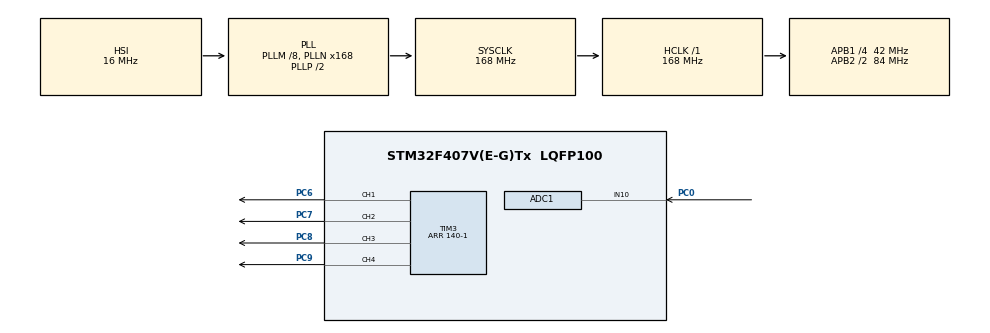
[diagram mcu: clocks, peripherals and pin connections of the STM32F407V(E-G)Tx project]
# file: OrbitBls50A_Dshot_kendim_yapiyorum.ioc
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ADC1.Channel-1\#ChannelRegularConversion=ADC_CHANNEL_10
ADC1.ContinuousConvMode=ENABLE
ADC1.NbrOfConversionFlag=1
ADC1.Rank-1\#ChannelRegularConversion=1
ADC1.SamplingTime-1\#ChannelRegularConversion=ADC_SAMPLETIME_84CYCLES
ADC1.master=1
Dma.Request0=TIM3_CH1/TRIG
Dma.Request1=TIM3_CH2
Dma.Request2=TIM3_CH3
Dma.Request3=TIM3_CH4/UP
Dma.TIM3_CH1/TRIG.0.Direction=DMA_MEMORY_TO_PERIPH
Dma.TIM3_CH1/TRIG.0.FIFOMode=DMA_FIFOMODE_DISABLE
Dma.TIM3_CH1/TRIG.0.Instance=DMA1_Stream4
Dma.TIM3_CH1/TRIG.0.MemDataAlignment=DMA_MDATAALIGN_HALFWORD
Dma.TIM3_CH1/TRIG.0.MemInc=DMA_MINC_ENABLE
Dma.TIM3_CH1/TRIG.0.Mode=DMA_NORMAL
Dma.TIM3_CH1/TRIG.0.PeriphDataAlignment=DMA_PDATAALIGN_HALFWORD
Dma.TIM3_CH1/TRIG.0.PeriphInc=DMA_PINC_DISABLE
Dma.TIM3_CH1/TRIG.0.Priority=DMA_PRIORITY_HIGH
Dma.TIM3_CH2.1.Direction=DMA_MEMORY_TO_PERIPH
Dma.TIM3_CH2.1.FIFOMode=DMA_FIFOMODE_DISABLE
Dma.TIM3_CH2.1.Instance=DMA1_Stream5
Dma.TIM3_CH2.1.MemDataAlignment=DMA_MDATAALIGN_HALFWORD
Dma.TIM3_CH2.1.MemInc=DMA_MINC_ENABLE
Dma.TIM3_CH2.1.Mode=DMA_NORMAL
Dma.TIM3_CH2.1.PeriphDataAlignment=DMA_PDATAALIGN_HALFWORD
Dma.TIM3_CH2.1.PeriphInc=DMA_PINC_DISABLE
Dma.TIM3_CH2.1.Priority=DMA_PRIORITY_HIGH
Dma.TIM3_CH3.2.Direction=DMA_MEMORY_TO_PERIPH
Dma.TIM3_CH3.2.FIFOMode=DMA_FIFOMODE_DISABLE
Dma.TIM3_CH3.2.Instance=DMA1_Stream7
Dma.TIM3_CH3.2.MemDataAlignment=DMA_MDATAALIGN_HALFWORD
Dma.TIM3_CH3.2.MemInc=DMA_MINC_ENABLE
Dma.TIM3_CH3.2.Mode=DMA_NORMAL
Dma.TIM3_CH3.2.PeriphDataAlignment=DMA_PDATAALIGN_HALFWORD
Dma.TIM3_CH3.2.PeriphInc=DMA_PINC_DISABLE
Dma.TIM3_CH3.2.Priority=DMA_PRIORITY_HIGH
Dma.TIM3_CH4/UP.3.Direction=DMA_MEMORY_TO_PERIPH
Dma.TIM3_CH4/UP.3.FIFOMode=DMA_FIFOMODE_DISABLE
Dma.TIM3_CH4/UP.3.Instance=DMA1_Stream2
Dma.TIM3_CH4/UP.3.MemDataAlignment=DMA_MDATAALIGN_HALFWORD
Dma.TIM3_CH4/UP.3.MemInc=DMA_MINC_ENABLE
Dma.TIM3_CH4/UP.3.Mode=DMA_NORMAL
Dma.TIM3_CH4/UP.3.PeriphDataAlignment=DMA_PDATAALIGN_HALFWORD
Dma.TIM3_CH4/UP.3.PeriphInc=DMA_PINC_DISABLE
Dma.TIM3_CH4/UP.3.Priority=DMA_PRIORITY_HIGH
Mcu.Family=STM32F4
Mcu.Name=STM32F407V(E-G)Tx
Mcu.Package=LQFP100
NVIC.DMA1_Stream2_IRQn=true\:0\:0\:false\:false\:true\:false\:true\:true
NVIC.DMA1_Stream4_IRQn=true\:0\:0\:false\:false\:true\:false\:true\:true
NVIC.DMA1_Stream5_IRQn=true\:0\:0\:false\:false\:true\:false\:true\:true
NVIC.DMA1_Stream7_IRQn=true\:0\:0\:false\:false\:true\:false\:true\:true
NVIC.PriorityGroup=NVIC_PRIORITYGROUP_4
NVIC.TIM4_IRQn=true\:0\:0\:false\:false\:true\:true\:true\:true
PC0.Signal=ADCx_IN10
PC6.Signal=S_TIM3_CH1
PC7.Signal=S_TIM3_CH2
PC8.Signal=S_TIM3_CH3
PC9.Signal=S_TIM3_CH4
ProjectManager.HeapSize=0x200
ProjectManager.StackSize=0x400
ProjectManager.TargetToolchain=STM32CubeIDE
RCC.48MHZClocksFreq_Value=84000000
RCC.AHBFreq_Value=168000000
RCC.APB1CLKDivider=RCC_HCLK_DIV4
RCC.APB1Freq_Value=42000000
RCC.APB1TimFreq_Value=84000000
RCC.APB2CLKDivider=RCC_HCLK_DIV2
RCC.APB2Freq_Value=84000000
RCC.APB2TimFreq_Value=168000000
RCC.CortexFreq_Value=168000000
RCC.HCLKFreq_Value=168000000
RCC.HSE_VALUE=25000000
RCC.HSI_VALUE=16000000
RCC.LSE_VALUE=32768
RCC.PLLM=8
RCC.PLLN=168
RCC.SYSCLKFreq_VALUE=168000000
RCC.SYSCLKSource=RCC_SYSCLKSOURCE_PLLCLK
RCC.VCOOutputFreq_Value=336000000
SH.ADCx_IN10.0=ADC1_IN10,IN10
SH.S_TIM3_CH1.0=TIM3_CH1,PWM Generation1 CH1
SH.S_TIM3_CH2.0=TIM3_CH2,PWM Generation2 CH2
SH.S_TIM3_CH3.0=TIM3_CH3,PWM Generation3 CH3
SH.S_TIM3_CH4.0=TIM3_CH4,PWM Generation4 CH4
TIM3.Channel-PWM\ Generation1\ CH1=TIM_CHANNEL_1
TIM3.Channel-PWM\ Generation2\ CH2=TIM_CHANNEL_2
TIM3.Channel-PWM\ Generation3\ CH3=TIM_CHANNEL_3
TIM3.Channel-PWM\ Generation4\ CH4=TIM_CHANNEL_4
TIM3.Period=140-1
TIM4.Period=100-1
TIM4.Prescaler=84-1
VP_TIM3_VS_ClockSourceINT.Mode=Internal
VP_TIM4_VS_ClockSourceINT.Mode=Internal
board=custom

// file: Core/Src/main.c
/* USER CODE BEGIN Header */
/**
  ******************************************************************************
  * @file           : main.c
  * @brief          : Main program body
  ******************************************************************************
  * @attention
  *
  * Copyright (c) 2026 STMicroelectronics.
  * All rights reserved.
  *
  * This software is licensed under terms that can be found in the LICENSE file
  * in the root directory of this software component.
  * If no LICENSE file comes with this software, it is provided AS-IS.
  *
  ******************************************************************************
  */
/* USER CODE END Header */
#include "main.h"

/* USER CODE BEGIN Includes */
#include "dshot.h"
/* USER CODE END Includes */

ADC_HandleTypeDef hadc1;

TIM_HandleTypeDef htim3;
TIM_HandleTypeDef htim4;
DMA_HandleTypeDef hdma_tim3_ch1_trig;
DMA_HandleTypeDef hdma_tim3_ch2;
DMA_HandleTypeDef hdma_tim3_ch3;
DMA_HandleTypeDef hdma_tim3_ch4_up;

/* USER CODE BEGIN PV */

uint8_t watchdog=0;
/* USER CODE END PV */

void SystemClock_Config(void);
static void MX_GPIO_Init(void);
static void MX_DMA_Init(void);
static void MX_TIM3_Init(void);
static void MX_ADC1_Init(void);
static void MX_TIM4_Init(void);

/* USER CODE BEGIN 0 */

uint16_t rpm = 50;
/* USER CODE END 0 */

int main(void)
{

  /* MCU Configuration--------------------------------------------------------*/

  /* Reset of all peripherals, Initializes the Flash interface and the Systick. */
  HAL_Init();

  /* Configure the system clock */
  SystemClock_Config();

  /* Initialize all configured peripherals */
  MX_GPIO_Init();
  MX_DMA_Init();
  MX_TIM3_Init();
  MX_ADC1_Init();
  MX_TIM4_Init();
  /* USER CODE BEGIN 2 */
  Dshot_Init_2(&htim3,&htim4,&hadc1);
  watchdog=1;

  Motors_Arm(4000,4000);

  /* USER CODE END 2 */

  /* Infinite loop */
  while (1)
  {

    /* USER CODE BEGIN 3 */
	 Get_ESC_Current(Read_RawADC_Current_Value());

	  //if(rpm==0){rpm=48;} else{rpm+=5;}
	  HAL_Delay(300);
	  if(rpm>=2047){rpm=48;}

  }
  /* USER CODE END 3 */
}

void SystemClock_Config(void)
{
  RCC_OscInitTypeDef RCC_OscInitStruct = {0};
  RCC_ClkInitTypeDef RCC_ClkInitStruct = {0};

  /** Configure the main internal regulator output voltage
  */
  __HAL_RCC_PWR_CLK_ENABLE();
  __HAL_PWR_VOLTAGESCALING_CONFIG(PWR_REGULATOR_VOLTAGE_SCALE1);

  /** Initializes the RCC Oscillators according to the specified parameters
  * in the RCC_OscInitTypeDef structure.
  */
  RCC_OscInitStruct.OscillatorType = RCC_OSCILLATORTYPE_HSI;
  RCC_OscInitStruct.HSIState = RCC_HSI_ON;
  RCC_OscInitStruct.HSICalibrationValue = RCC_HSICALIBRATION_DEFAULT;
  RCC_OscInitStruct.PLL.PLLState = RCC_PLL_ON;
  RCC_OscInitStruct.PLL.PLLSource = RCC_PLLSOURCE_HSI;
  RCC_OscInitStruct.PLL.PLLM = 8;
  RCC_OscInitStruct.PLL.PLLN = 168;
  RCC_OscInitStruct.PLL.PLLP = RCC_PLLP_DIV2;
  RCC_OscInitStruct.PLL.PLLQ = 4;
  if (HAL_RCC_OscConfig(&RCC_OscInitStruct) != HAL_OK)
  {
    Error_Handler();
  }

  /** Initializes the CPU, AHB and APB buses clocks
  */
  RCC_ClkInitStruct.ClockType = RCC_CLOCKTYPE_HCLK|RCC_CLOCKTYPE_SYSCLK
                              |RCC_CLOCKTYPE_PCLK1|RCC_CLOCKTYPE_PCLK2;
  RCC_ClkInitStruct.SYSCLKSource = RCC_SYSCLKSOURCE_PLLCLK;
  RCC_ClkInitStruct.AHBCLKDivider = RCC_SYSCLK_DIV1;
  RCC_ClkInitStruct.APB1CLKDivider = RCC_HCLK_DIV4;
  RCC_ClkInitStruct.APB2CLKDivider = RCC_HCLK_DIV2;

  if (HAL_RCC_ClockConfig(&RCC_ClkInitStruct, FLASH_LATENCY_5) != HAL_OK)
  {
    Error_Handler();
  }
}

static void MX_ADC1_Init(void)
{

  ADC_ChannelConfTypeDef sConfig = {0};

  /** Configure the global features of the ADC (Clock, Resolution, Data Alignment and number of conversion)
  */
  hadc1.Instance = ADC1;
  hadc1.Init.ClockPrescaler = ADC_CLOCK_SYNC_PCLK_DIV4;
  hadc1.Init.Resolution = ADC_RESOLUTION_12B;
  hadc1.Init.ScanConvMode = DISABLE;
  hadc1.Init.ContinuousConvMode = ENABLE;
  hadc1.Init.DiscontinuousConvMode = DISABLE;
  hadc1.Init.ExternalTrigConvEdge = ADC_EXTERNALTRIGCONVEDGE_NONE;
  hadc1.Init.ExternalTrigConv = ADC_SOFTWARE_START;
  hadc1.Init.DataAlign = ADC_DATAALIGN_RIGHT;
  hadc1.Init.NbrOfConversion = 1;
  hadc1.Init.DMAContinuousRequests = DISABLE;
  hadc1.Init.EOCSelection = ADC_EOC_SINGLE_CONV;
  if (HAL_ADC_Init(&hadc1) != HAL_OK)
  {
    Error_Handler();
  }

  /** Configure for the selected ADC regular channel its corresponding rank in the sequencer and its sample time.
  */
  sConfig.Channel = ADC_CHANNEL_10;
  sConfig.Rank = 1;
  sConfig.SamplingTime = ADC_SAMPLETIME_84CYCLES;
  if (HAL_ADC_ConfigChannel(&hadc1, &sConfig) != HAL_OK)
  {
    Error_Handler();
  }

}

static void MX_TIM3_Init(void)
{

  TIM_ClockConfigTypeDef sClockSourceConfig = {0};
  TIM_MasterConfigTypeDef sMasterConfig = {0};
  TIM_OC_InitTypeDef sConfigOC = {0};

  htim3.Instance = TIM3;
  htim3.Init.Prescaler = 0;
  htim3.Init.CounterMode = TIM_COUNTERMODE_UP;
  htim3.Init.Period = 140-1;
  htim3.Init.ClockDivision = TIM_CLOCKDIVISION_DIV1;
  htim3.Init.AutoReloadPreload = TIM_AUTORELOAD_PRELOAD_DISABLE;
  if (HAL_TIM_Base_Init(&htim3) != HAL_OK)
  {
    Error_Handler();
  }
  sClockSourceConfig.ClockSource = TIM_CLOCKSOURCE_INTERNAL;
  if (HAL_TIM_ConfigClockSource(&htim3, &sClockSourceConfig) != HAL_OK)
  {
    Error_Handler();
  }
  if (HAL_TIM_PWM_Init(&htim3) != HAL_OK)
  {
    Error_Handler();
  }
  sMasterConfig.MasterOutputTrigger = TIM_TRGO_RESET;
  sMasterConfig.MasterSlaveMode = TIM_MASTERSLAVEMODE_DISABLE;
  if (HAL_TIMEx_MasterConfigSynchronization(&htim3, &sMasterConfig) != HAL_OK)
  {
    Error_Handler();
  }
  sConfigOC.OCMode = TIM_OCMODE_PWM1;
  sConfigOC.Pulse = 0;
  sConfigOC.OCPolarity = TIM_OCPOLARITY_HIGH;
  sConfigOC.OCFastMode = TIM_OCFAST_DISABLE;
  if (HAL_TIM_PWM_ConfigChannel(&htim3, &sConfigOC, TIM_CHANNEL_1) != HAL_OK)
  {
    Error_Handler();
  }
  if (HAL_TIM_PWM_ConfigChannel(&htim3, &sConfigOC, TIM_CHANNEL_2) != HAL_OK)
  {
    Error_Handler();
  }
  if (HAL_TIM_PWM_ConfigChannel(&htim3, &sConfigOC, TIM_CHANNEL_3) != HAL_OK)
  {
    Error_Handler();
  }
  if (HAL_TIM_PWM_ConfigChannel(&htim3, &sConfigOC, TIM_CHANNEL_4) != HAL_OK)
  {
    Error_Handler();
  }
  HAL_TIM_MspPostInit(&htim3);

}

static void MX_TIM4_Init(void)
{

  TIM_ClockConfigTypeDef sClockSourceConfig = {0};
  TIM_MasterConfigTypeDef sMasterConfig = {0};

  htim4.Instance = TIM4;
  htim4.Init.Prescaler = 84-1;
  htim4.Init.CounterMode = TIM_COUNTERMODE_UP;
  htim4.Init.Period = 100-1;
  htim4.Init.ClockDivision = TIM_CLOCKDIVISION_DIV1;
  htim4.Init.AutoReloadPreload = TIM_AUTORELOAD_PRELOAD_DISABLE;
  if (HAL_TIM_Base_Init(&htim4) != HAL_OK)
  {
    Error_Handler();
  }
  sClockSourceConfig.ClockSource = TIM_CLOCKSOURCE_INTERNAL;
  if (HAL_TIM_ConfigClockSource(&htim4, &sClockSourceConfig) != HAL_OK)
  {
    Error_Handler();
  }
  sMasterConfig.MasterOutputTrigger = TIM_TRGO_RESET;
  sMasterConfig.MasterSlaveMode = TIM_MASTERSLAVEMODE_DISABLE;
  if (HAL_TIMEx_MasterConfigSynchronization(&htim4, &sMasterConfig) != HAL_OK)
  {
    Error_Handler();
  }

}

static void MX_DMA_Init(void)
{

  /* DMA controller clock enable */
  __HAL_RCC_DMA1_CLK_ENABLE();

  /* DMA interrupt init */
  /* DMA1_Stream2_IRQn interrupt configuration */
  HAL_NVIC_SetPriority(DMA1_Stream2_IRQn, 0, 0);
  HAL_NVIC_EnableIRQ(DMA1_Stream2_IRQn);
  /* DMA1_Stream4_IRQn interrupt configuration */
  HAL_NVIC_SetPriority(DMA1_Stream4_IRQn, 0, 0);
  HAL_NVIC_EnableIRQ(DMA1_Stream4_IRQn);
  /* DMA1_Stream5_IRQn interrupt configuration */
  HAL_NVIC_SetPriority(DMA1_Stream5_IRQn, 0, 0);
  HAL_NVIC_EnableIRQ(DMA1_Stream5_IRQn);
  /* DMA1_Stream7_IRQn interrupt configuration */
  HAL_NVIC_SetPriority(DMA1_Stream7_IRQn, 0, 0);
  HAL_NVIC_EnableIRQ(DMA1_Stream7_IRQn);

}

static void MX_GPIO_Init(void)
{

  /* GPIO Ports Clock Enable */
  __HAL_RCC_GPIOC_CLK_ENABLE();

}

/* USER CODE BEGIN 4 */
void HAL_TIM_PWM_PulseFinishedCallback(TIM_HandleTypeDef *htim)
{
	Dshot_Frame_End_Callback(htim);
}

void HAL_TIM_PeriodElapsedCallback(TIM_HandleTypeDef *htim)
{

	uint16_t motor_hizlari[4] = {rpm, 0, 0, 0};
	Dshot_Communicator_Timer_Callback(htim, motor_hizlari);
}
/* USER CODE END 4 */

void Error_Handler(void)
{
  __disable_irq();
  while (1)
  {
  }
}
